# AE350_4GB register map
Vendor: Andes Technology; Series: AE350; File version: 1.3.0
Registers are 32-bit, read-write, reset 0x0 unless marked. A register's access mark holds for its fields unless they carry their own. Offsets are from the block's base; [hi:lo] are bit positions; {n}, {i} and the like mark numbered series.

## WDT — WDT Controller Registers
Base 0xF0500000
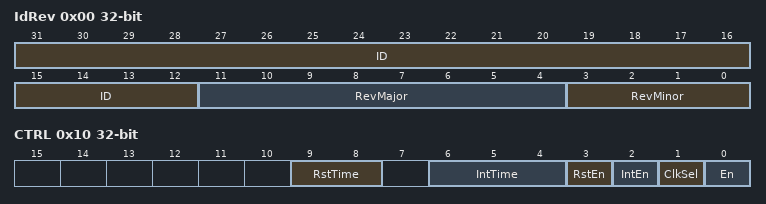
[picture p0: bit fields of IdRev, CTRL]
0x00 IdRev ro reset not defined — ID and Revision Register
  [31:12] ID — ID number for ATCWDT200
  [11:4] RevMajor — Major revision number
  [3:0] RevMinor — Minor revision number
0x10 CTRL — Write-Protected Watchdog Timer Control Register
  [9:8] RstTime — The time interval of the reset stage
  [6:4] IntTime — The timer interval of the interrupt stage
  [3] RstEn — Enable or disable the watchdog reset
  [2] IntEn — Enable or disable the watchdog interrupt
  [1] ClkSel — Clock source of timer
  [0] En — Enable or disable the watchdog timer
0x14 RESTART wo — Watchdog Timer Restart Register
  [15:0] Restart — Write the magic number
0x18 WEN wo — Watchdog Timer Write Enable Register
  [15:0] Wen — Write the magic number
0x1C ST — Watchdog Timer Status Register
  [0] IntExpired — The status of the watchdog interrupt timer

## RTC — RTC Controller Registers
Base 0xF0600000
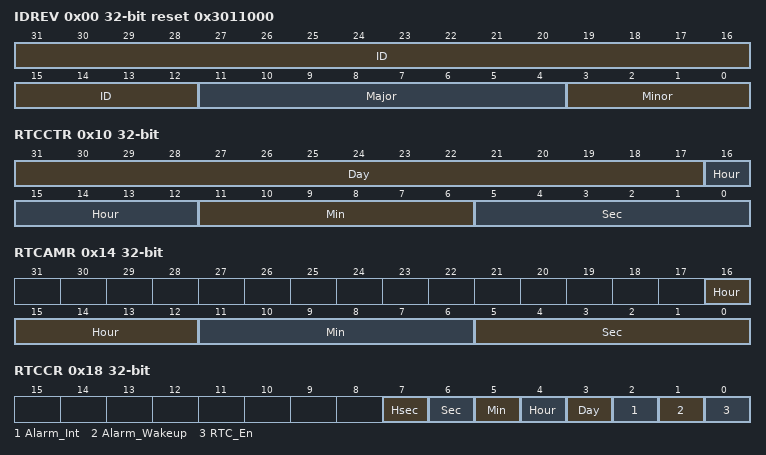
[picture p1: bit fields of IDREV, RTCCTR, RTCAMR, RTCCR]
0x00 IDREV ro reset 0x3011000 — ID and Revision Register
  [31:12] ID — ID number for ATCRTC100
  [11:4] Major — Major revision number
  [3:0] Minor — Minor revision number
0x10 RTCCTR — RTC Register
  [31:17] Day — Day passed after RTC enabled
  [16:12] Hour — Hour field of current time
  [11:6] Min — Minute field of current time
  [5:0] Sec — Second field of current time
0x14 RTCAMR — RTC Alarm Register
  [16:12] Hour — Hour field of alarm setting
  [11:6] Min — Minute field of alarm setting
  [5:0] Sec — Second field of alarm setting
0x18 RTCCR — RTC Control Register
  [7] Hsec — Enable half-second interrupt
  [6] Sec — Enable "second" interrupt
  [5] Min — Enable minute interrupt
  [4] Hour — Enable hour interrupt
  [3] Day — Enable day interrupt
  [2] Alarm_Int — Enable alarm interrupt
  [1] Alarm_Wakeup — Enable alarm wakeup signal
  [0] RTC_En — Enable RTC
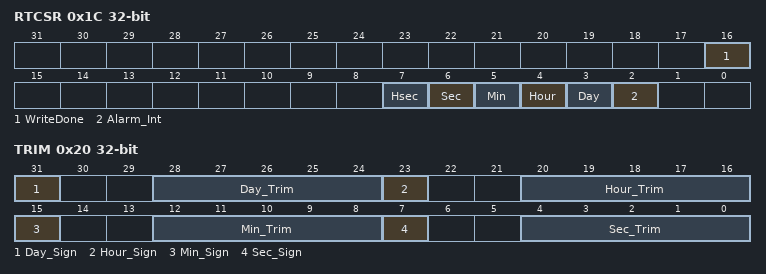
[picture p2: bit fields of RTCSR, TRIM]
0x1C RTCSR — RTC Status Register
  [16] WriteDone ro — This bit indicates the synchronization progress of RTC register updates
  [7] Hsec — Half-second interrupt status,write 1 to clear
  [6] Sec — Second interrupt status
  [5] Min — Minute interrupt status
  [4] Hour — Hour interrupt status
  [3] Day — Day interrupt status
  [2] Alarm_Int — Alarm interrupt status
0x20 TRIM — Digital Trimming Register
  [31] Day_Sign — Sign bit for the trimming value for the second on the day boundary
  [28:24] Day_Trim — Digital trimming value for the second on the day boundary
  [23] Hour_Sign — Sign bit for the trimming value for the second on the hour boundary
  [20:16] Hour_Trim — Digital trimming value for the second on the hour boundary
  [15] Min_Sign — Sign bit for the trimming value for the second on the minute boundary
  [12:8] Min_Trim — Digital trimming value for the second on the minute boundary
  [7] Sec_Sign — Sign bit for the trimming value for the rest of seconds
  [4:0] Sec_Trim — Digital trimming value for the rest of seconds

## GPIO — GPIO Controller Registers
Base 0xF0700000
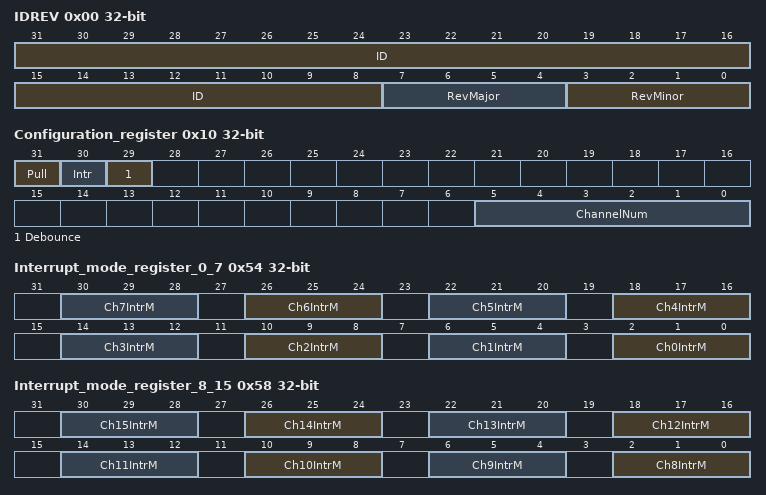
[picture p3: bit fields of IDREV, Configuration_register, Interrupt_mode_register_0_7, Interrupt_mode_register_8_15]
0x00 IDREV ro reset not defined — ID and Revision Register
  [31:8] ID — ID number for ATCGPIO100
  [7:4] RevMajor — Major revision number
  [3:0] RevMinor — Minor revision number
0x10 Configuration_register ro reset not defined
  [31] Pull — Pull option
  [30] Intr — Interrupt option
  [29] Debounce — De-bounce option
  [5:0] ChannelNum — Number of channels
0x20 Channel_data_in_register ro
  [?] FIELD_1 rw
0x24 Channel_data_out_register
  [?] FIELD_1
0x28 Channel_direction_register
  [31:0] ChannelDir ro — GPIO channel direction
0x2C Channel_data_out_clear_register wo
  [?] FIELD_1 rw
0x30 Channel_data_out_set_register wo
  [?] FIELD_1 rw
0x40 Pull_enable_register
  [?] FIELD_1
0x44 Pull_type_register
  [31:0] PullType ro — GPIO pull control
0x50 Interrupt_enable_register
  [?] FIELD_1
0x54 Interrupt_mode_register_0_7
  [4n+2:4n] Ch{n}IntrM (n=0..7) — Channel {n} interrupt mode
0x58 Interrupt_mode_register_8_15
  [4n-30:4n-32] Ch{n}IntrM (n=8..15) — Channel {n} interrupt mode
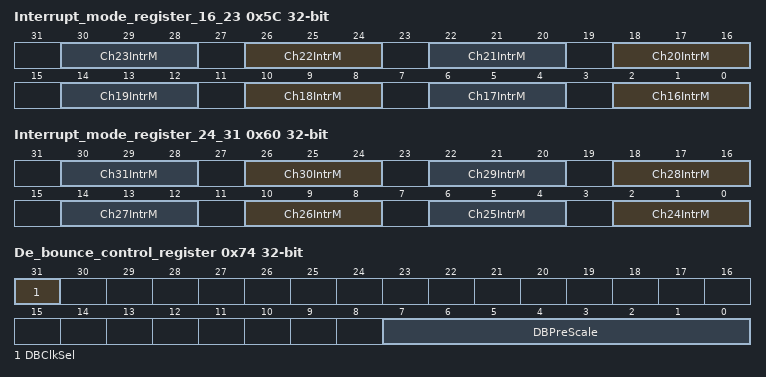
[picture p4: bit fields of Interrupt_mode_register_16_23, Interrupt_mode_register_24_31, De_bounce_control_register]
0x5C Interrupt_mode_register_16_23
  [4n-62:4n-64] Ch{n}IntrM (n=16..23) — Channel {n} interrupt mode
0x60 Interrupt_mode_register_24_31
  [4n-94:4n-96] Ch{n}IntrM (n=24..31) — Channel {n} interrupt mode
0x64 Interrupt_status_register
  [31:0] IntrStatus — The interrupt status of the corresponding channel
0x70 De_bounce_enable_register
  [?] FIELD_1
0x74 De_bounce_control_register
  [31] DBClkSel — GPIO de-bounce clock source selection
  [7:0] DBPreScale — GPIO pre-scale base
